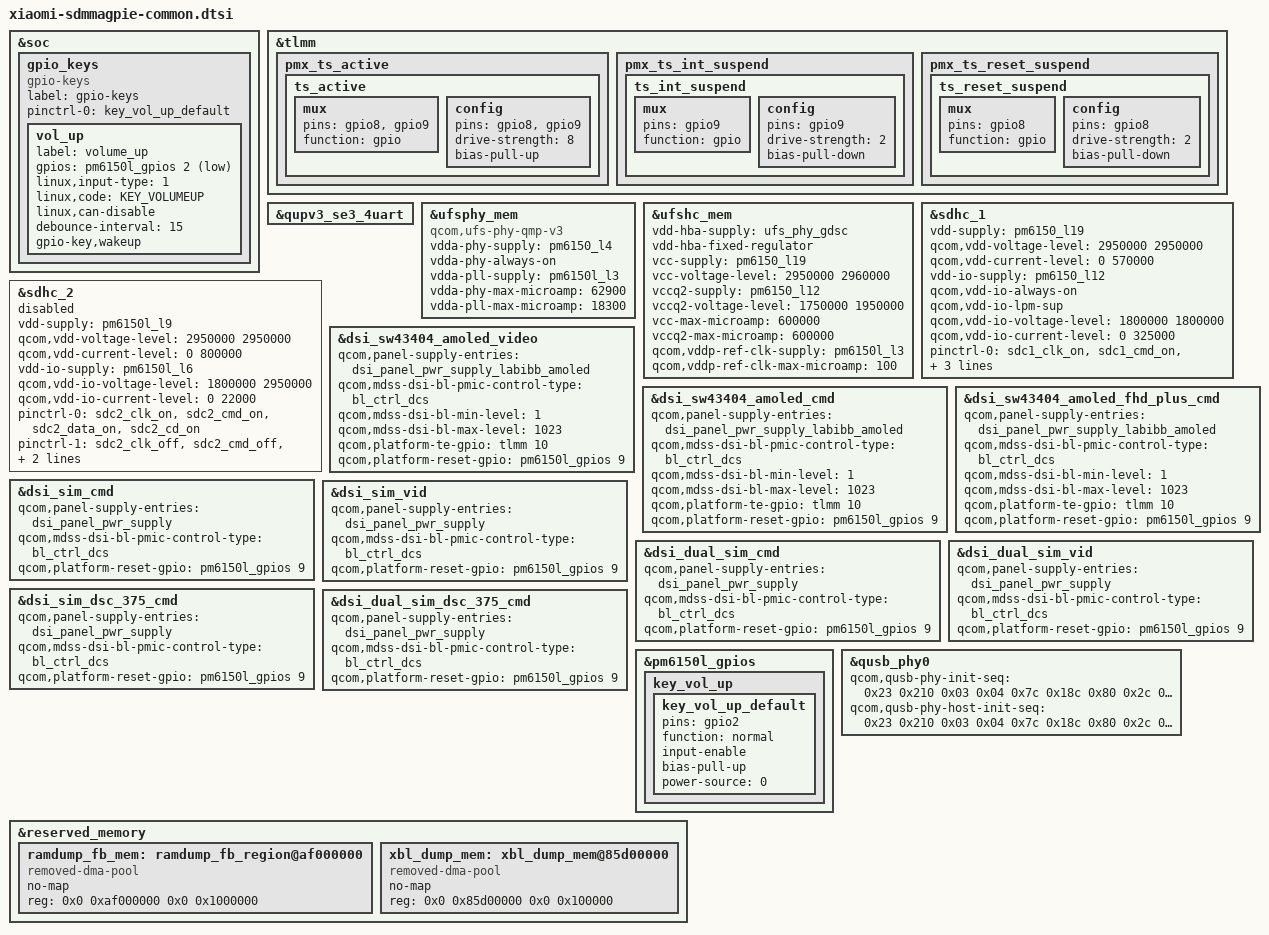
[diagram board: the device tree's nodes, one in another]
/* Copyright (c) 2018, The Linux Foundation. All rights reserved.
 * Copyright (C) 2021 XiaoMi, Inc.
 *
 * This program is free software; you can redistribute it and/or modify
 * it under the terms of the GNU General Public License version 2 and
 * only version 2 as published by the Free Software Foundation.
 *
 * This program is distributed in the hope that it will be useful,
 * but WITHOUT ANY WARRANTY; without even the implied warranty of
 * MERCHANTABILITY or FITNESS FOR A PARTICULAR PURPOSE.  See the
 * GNU General Public License for more details.
 */

#include <dt-bindings/gpio/gpio.h>
#include <dt-bindings/pinctrl/qcom,pmic-gpio.h>
#include <dt-bindings/iio/qcom,spmi-vadc.h>
#include <dt-bindings/input/input.h>
#include "sdmmagpie-thermal-overlay.dtsi"

#include "sdmmagpie-sde-display.dtsi"

&soc {
	/*
	fpc1020 {
		compatible = "fpc,fpc1020";
		interrupt-parent = <&tlmm>;
		interrupts = <90 0>;
		fpc,gpio_rst = <&tlmm 91 0x0>;
		fpc,gpio_irq = <&tlmm 90 0>;
		vcc_spi-supply = <&pm6150_l10>;
		vdd_io-supply  = <&pm6150_l10>;
		vdd_ana-supply = <&pm6150_l10>;
		fpc,enable-on-boot;
		pinctrl-names = "fpc1020_reset_reset",
				"fpc1020_reset_active",
				"fpc1020_irq_active";
		pinctrl-0 = <&fpc_reset_low>;
		pinctrl-1 = <&fpc_reset_high>;
		pinctrl-2 = <&fpc_int_low>;
	};
	*/
};

&tlmm {
	pmx_ts_active {
		ts_active: ts_active {
			mux {
				pins = "gpio8", "gpio9";
				function = "gpio";
			};

			config {
				pins = "gpio8", "gpio9";
				drive-strength = <8>;
				bias-pull-up;
			};
		};
	};

	pmx_ts_int_suspend {
		ts_int_suspend: ts_int_suspend {
			mux {
				pins = "gpio9";
				function = "gpio";
			};

			config {
				pins = "gpio9";
				drive-strength = <2>;
				bias-pull-down;
			};
		};
	};

	pmx_ts_reset_suspend {
		ts_reset_suspend: ts_reset_suspend {
				mux {
					pins = "gpio8";
					function = "gpio";
				};

				config {
					pins = "gpio8";
					drive-strength = <2>;
					bias-pull-down;
				};
			};
	};

};

&qupv3_se3_4uart {
	status = "ok";
};

&ufsphy_mem {
	compatible = "qcom,ufs-phy-qmp-v3";

	vdda-phy-supply = <&pm6150_l4>; /* 0.88v */
	vdda-phy-always-on;
	vdda-pll-supply = <&pm6150l_l3>; /* 1.2v */
	vdda-phy-max-microamp = <62900>;
	vdda-pll-max-microamp = <18300>;

	status = "ok";
};

&ufshc_mem {
	vdd-hba-supply = <&ufs_phy_gdsc>;
	vdd-hba-fixed-regulator;
	vcc-supply = <&pm6150_l19>;
	vcc-voltage-level = <2950000 2960000>;
	vccq2-supply = <&pm6150_l12>;
	vccq2-voltage-level = <1750000 1950000>;
	vcc-max-microamp = <600000>;
	vccq2-max-microamp = <600000>;

	qcom,vddp-ref-clk-supply = <&pm6150l_l3>;
	qcom,vddp-ref-clk-max-microamp = <100>;

	status = "ok";
};

&sdhc_1 {
	vdd-supply = <&pm6150_l19>;
	qcom,vdd-voltage-level = <2950000 2950000>;
	qcom,vdd-current-level = <0 570000>;

	vdd-io-supply = <&pm6150_l12>;
	qcom,vdd-io-always-on;
	qcom,vdd-io-lpm-sup;
	qcom,vdd-io-voltage-level = <1800000 1800000>;
	qcom,vdd-io-current-level = <0 325000>;

	pinctrl-names = "active", "sleep";
	pinctrl-0 = <&sdc1_clk_on &sdc1_cmd_on &sdc1_data_on &sdc1_rclk_on>;
	pinctrl-1 = <&sdc1_clk_off &sdc1_cmd_off &sdc1_data_off &sdc1_rclk_off>;

	status = "ok";
};

&sdhc_2 {
	vdd-supply = <&pm6150l_l9>;
	qcom,vdd-voltage-level = <2950000 2950000>;
	qcom,vdd-current-level = <0 800000>;

	vdd-io-supply = <&pm6150l_l6>;
	qcom,vdd-io-voltage-level = <1800000 2950000>;
	qcom,vdd-io-current-level = <0 22000>;

	pinctrl-names = "active", "sleep";
	pinctrl-0 = <&sdc2_clk_on  &sdc2_cmd_on &sdc2_data_on &sdc2_cd_on>;
	pinctrl-1 = <&sdc2_clk_off &sdc2_cmd_off &sdc2_data_off &sdc2_cd_off>;

	cd-gpios = <&tlmm 69 GPIO_ACTIVE_HIGH>;

	status = "disabled";
};

&dsi_sw43404_amoled_video {
	qcom,panel-supply-entries = <&dsi_panel_pwr_supply_labibb_amoled>;
	qcom,mdss-dsi-bl-pmic-control-type = "bl_ctrl_dcs";
	qcom,mdss-dsi-bl-min-level = <1>;
	qcom,mdss-dsi-bl-max-level = <1023>;
	qcom,platform-te-gpio = <&tlmm 10 0>;
	qcom,platform-reset-gpio = <&pm6150l_gpios 9 0>;
};

&dsi_sw43404_amoled_cmd {
	qcom,panel-supply-entries = <&dsi_panel_pwr_supply_labibb_amoled>;
	qcom,mdss-dsi-bl-pmic-control-type = "bl_ctrl_dcs";
	qcom,mdss-dsi-bl-min-level = <1>;
	qcom,mdss-dsi-bl-max-level = <1023>;
	qcom,platform-te-gpio = <&tlmm 10 0>;
	qcom,platform-reset-gpio = <&pm6150l_gpios 9 0>;
};

&dsi_sw43404_amoled_fhd_plus_cmd {
	qcom,panel-supply-entries = <&dsi_panel_pwr_supply_labibb_amoled>;
	qcom,mdss-dsi-bl-pmic-control-type = "bl_ctrl_dcs";
	qcom,mdss-dsi-bl-min-level = <1>;
	qcom,mdss-dsi-bl-max-level = <1023>;
	qcom,platform-te-gpio = <&tlmm 10 0>;
	qcom,platform-reset-gpio = <&pm6150l_gpios 9 0>;
};

&dsi_sim_cmd {
	qcom,panel-supply-entries = <&dsi_panel_pwr_supply>;
	qcom,mdss-dsi-bl-pmic-control-type = "bl_ctrl_dcs";
	qcom,platform-reset-gpio = <&pm6150l_gpios 9 0>;
};

&dsi_sim_vid {
	qcom,panel-supply-entries = <&dsi_panel_pwr_supply>;
	qcom,mdss-dsi-bl-pmic-control-type = "bl_ctrl_dcs";
	qcom,platform-reset-gpio = <&pm6150l_gpios 9 0>;
};

&dsi_dual_sim_cmd {
	qcom,panel-supply-entries = <&dsi_panel_pwr_supply>;
	qcom,mdss-dsi-bl-pmic-control-type = "bl_ctrl_dcs";
	qcom,platform-reset-gpio = <&pm6150l_gpios 9 0>;
};

&dsi_dual_sim_vid {
	qcom,panel-supply-entries = <&dsi_panel_pwr_supply>;
	qcom,mdss-dsi-bl-pmic-control-type = "bl_ctrl_dcs";
	qcom,platform-reset-gpio = <&pm6150l_gpios 9 0>;
};

&dsi_sim_dsc_375_cmd {
	qcom,panel-supply-entries = <&dsi_panel_pwr_supply>;
	qcom,mdss-dsi-bl-pmic-control-type = "bl_ctrl_dcs";
	qcom,platform-reset-gpio = <&pm6150l_gpios 9 0>;
};

&dsi_dual_sim_dsc_375_cmd {
	qcom,panel-supply-entries = <&dsi_panel_pwr_supply>;
	qcom,mdss-dsi-bl-pmic-control-type = "bl_ctrl_dcs";
	qcom,platform-reset-gpio = <&pm6150l_gpios 9 0>;
};

&pm6150l_gpios {
	key_vol_up {
		key_vol_up_default: key_vol_up_default {
			pins = "gpio2";
			function = "normal";
			input-enable;
			bias-pull-up;
			power-source = <0>;
		};
	};
};

&soc {
	gpio_keys {
		compatible = "gpio-keys";
		label = "gpio-keys";

		pinctrl-names = "default";
		pinctrl-0 = <&key_vol_up_default>;

		vol_up {
			label = "volume_up";
			gpios = <&pm6150l_gpios 2 GPIO_ACTIVE_LOW>;
			linux,input-type = <1>;
			linux,code = <KEY_VOLUMEUP>;
			linux,can-disable;
			debounce-interval = <15>;
			gpio-key,wakeup;
		};
	};
};

&qusb_phy0 {
	qcom,qusb-phy-init-seq =
		/* <value reg_offset> */
		   <0x23 0x210 /* PWR_CTRL1 */
		    0x03 0x04  /* PLL_ANALOG_CONTROLS_TWO */
		    0x7c 0x18c /* PLL_CLOCK_INVERTERS */
		    0x80 0x2c  /* PLL_CMODE */
		    0x0a 0x184 /* PLL_LOCK_DELAY */
		    0x19 0xb4  /* PLL_DIGITAL_TIMERS_TWO */
		    0x40 0x194 /* PLL_BIAS_CONTROL_1 */
		    0x1c 0x198 /* PLL_BIAS_CONTROL_2 */
		    0x21 0x214 /* PWR_CTRL2 */
		    0x00 0x220 /* IMP_CTRL1 */
		    0x18 0x224 /* IMP_CTRL2 */
		    0x16 0x240 /* TUNE1 */
		    0x29 0x244 /* TUNE2 */
		    0xca 0x248 /* TUNE3 */
		    0x02 0x24c /* TUNE4 */
		    0x03 0x250 /* TUNE5 */
		    0x00 0x23c /* CHG_CTRL2 */
		    0x22 0x210>; /* PWR_CTRL1 */

	qcom,qusb-phy-host-init-seq =
		/* <value reg_offset> */
		   <0x23 0x210 /* PWR_CTRL1 */
		    0x03 0x04  /* PLL_ANALOG_CONTROLS_TWO */
		    0x7c 0x18c /* PLL_CLOCK_INVERTERS */
		    0x80 0x2c  /* PLL_CMODE */
		    0x0a 0x184 /* PLL_LOCK_DELAY */
		    0x19 0xb4  /* PLL_DIGITAL_TIMERS_TWO */
		    0x40 0x194 /* PLL_BIAS_CONTROL_1 */
		    0x20 0x198 /* PLL_BIAS_CONTROL_2 */
		    0x21 0x214 /* PWR_CTRL2 */
		    0x00 0x220 /* IMP_CTRL1 */
		    0x18 0x224 /* IMP_CTRL2 */
		    0x37 0x240 /* TUNE1 */
		    0x29 0x244 /* TUNE2 */
		    0xca 0x248 /* TUNE3 */
		    0x04 0x24c /* TUNE4 */
		    0x03 0x250 /* TUNE5 */
		    0x00 0x23c /* CHG_CTRL2 */
		    0x22 0x210>; /* PWR_CTRL1 */
};

&reserved_memory {
		ramdump_fb_mem: ramdump_fb_region@af000000 {
			compatible = "removed-dma-pool";
			no-map;
			reg = <0x0 0xaf000000 0x0 0x1000000>;
		};

		xbl_dump_mem: xbl_dump_mem@85d00000 {
			compatible = "removed-dma-pool";
			no-map;
			reg = <0x0 0x85d00000 0x0 0x100000>;
		};
};
